# PIC32CM5164LS60064 register map
Vendor: Microchip Technology; Series: PIC32CMLS60; File version: 0
CPU: CM23 r0p0, selectable endian, MPU, no FPU, 2 interrupt priority bits
Registers are 32-bit, read-write, reset 0x0 unless marked. A register's access mark holds for its fields unless they carry their own. Offsets are from the block's base; [hi:lo] are bit positions; {n}, {i} and the like mark numbered series.

## PAC — Peripheral Access Controller
Base 0x40000000; register names take the prefix PAC_
Same registers: PAC_SEC 0x40000200 (register names take the prefix PAC_SEC_)
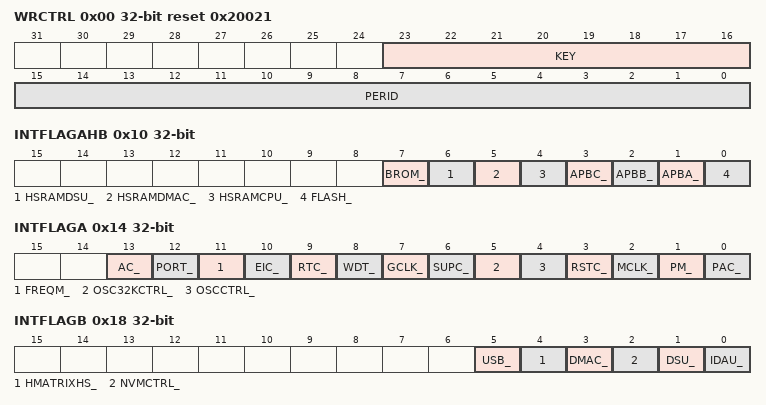
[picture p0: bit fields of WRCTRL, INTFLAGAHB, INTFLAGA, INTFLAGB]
0x00 WRCTRL reset 0x20021 — Write control
  [23:16] KEY — Peripheral access control key
    0=OFF (No action); 1=CLR (Clear protection); 2=SET (Set protection); 3=SETLCK (Set and lock protection); 4=SETSEC (Set IP secure); 5=SETNONSEC (Set IP non-secure); 6=SECLOCK (Lock IP security value)
  [15:0] PERID — Peripheral identifier
0x04 EVCTRL 8-bit — Event control
  [0] ERREO — Peripheral acess error event output
0x08 INTENCLR 8-bit — Interrupt enable clear
  [0] ERR — Peripheral access error interrupt disable
0x09 INTENSET 8-bit — Interrupt enable set
  [0] ERR — Peripheral access error interrupt enable
0x10 INTFLAGAHB — Bridge interrupt flag status
  [7] BROM_, [6] HSRAMDSU_, [5] HSRAMDMAC_, [4] HSRAMCPU_, [3] APBC_, [2] APBB_, [1] APBA_, [0] FLASH_
0x14 INTFLAGA — Peripheral interrupt flag status - Bridge A
  [13] AC_, [12] PORT_, [11] FREQM_, [10] EIC_, [9] RTC_, [8] WDT_, [7] GCLK_, [6] SUPC_, [5] OSC32KCTRL_, [4] OSCCTRL_, [3] RSTC_, [2] MCLK_, [1] PM_, [0] PAC_
0x18 INTFLAGB — Peripheral interrupt flag status - Bridge B
  [5] USB_, [4] HMATRIXHS_, [3] DMAC_, [2] NVMCTRL_, [1] DSU_, [0] IDAU_
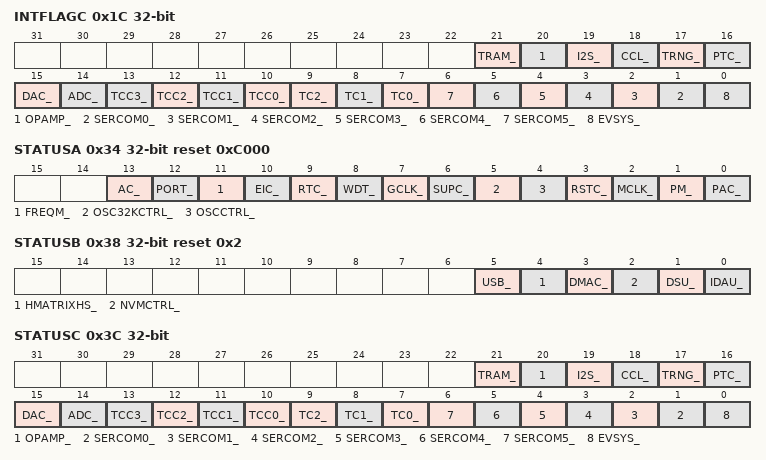
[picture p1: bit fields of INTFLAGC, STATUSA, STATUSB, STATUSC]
0x1C INTFLAGC — Peripheral interrupt flag status - Bridge C
  [21] TRAM_, [20] OPAMP_, [19] I2S_, [18] CCL_, [17] TRNG_, [16] PTC_, [15] DAC_, [14] ADC_, [n+10] TCC{n}_ (n=0..3), [9] TC2_, [8] TC1_, [7] TC0_, [n+1] SERCOM{n}_ (n=0..5), [0] EVSYS_
0x34 STATUSA ro reset 0xC000 — Peripheral write protection status - Bridge A
  [13] AC_ — AC APB Protect Enable
  [12] PORT_ — PORT APB Protect Enable
  [11] FREQM_ — FREQM APB Protect Enable
  [10] EIC_ — EIC APB Protect Enable
  [9] RTC_ — RTC APB Protect Enable
  [8] WDT_ — WDT APB Protect Enable
  [7] GCLK_ — GCLK APB Protect Enable
  [6] SUPC_ — SUPC APB Protect Enable
  [5] OSC32KCTRL_ — OSC32KCTRL APB Protect Enable
  [4] OSCCTRL_ — OSCCTRL APB Protect Enable
  [3] RSTC_ — RSTC APB Protect Enable
  [2] MCLK_ — MCLK APB Protect Enable
  [1] PM_ — PM APB Protect Enable
  [0] PAC_ — PAC APB Protect Enable
0x38 STATUSB ro reset 0x2 — Peripheral write protection status - Bridge B
  [5] USB_ — USB APB Protect Enable
  [4] HMATRIXHS_ — HMATRIXHS APB Protect Enable
  [3] DMAC_ — DMAC APB Protect Enable
  [2] NVMCTRL_ — NVMCTRL APB Protect Enable
  [1] DSU_ — DSU APB Protect Enable
  [0] IDAU_ — IDAU APB Protect Enable
0x3C STATUSC ro — Peripheral write protection status - Bridge C
  [21] TRAM_ — TRAM APB Protect Enable
  [20] OPAMP_ — OPAMP APB Protect Enable
  [19] I2S_ — I2S APB Protect Enable
  [18] CCL_ — CCL APB Protect Enable
  [17] TRNG_ — TRNG APB Protect Enable
  [16] PTC_ — PTC APB Protect Enable
  [15] DAC_ — DAC APB Protect Enable
  [14] ADC_ — ADC APB Protect Enable
  [n+10] TCC{n}_ (n=0..3) — TCC{n} APB Protect Enable
  [9] TC2_ — TC2 APB Protect Enable
  [8] TC1_ — TC1 APB Protect Enable
  [7] TC0_ — TC0 APB Protect Enable
  [n+1] SERCOM{n}_ (n=0..5) — SERCOM{n} APB Protect Enable
  [0] EVSYS_ — EVSYS APB Protect Enable
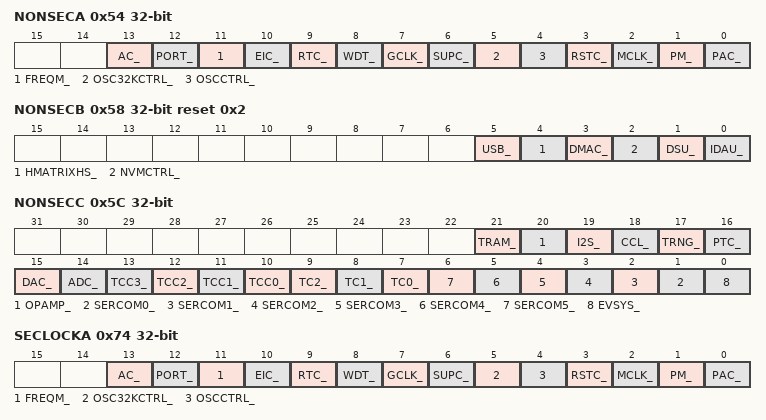
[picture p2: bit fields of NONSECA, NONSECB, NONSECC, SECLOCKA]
0x54 NONSECA ro — Peripheral non-secure status - Bridge A
  [13] AC_ — AC Non-Secure
  [12] PORT_ — PORT Non-Secure
  [11] FREQM_ — FREQM Non-Secure
  [10] EIC_ — EIC Non-Secure
  [9] RTC_ — RTC Non-Secure
  [8] WDT_ — WDT Non-Secure
  [7] GCLK_ — GCLK Non-Secure
  [6] SUPC_ — SUPC Non-Secure
  [5] OSC32KCTRL_ — OSC32KCTRL Non-Secure
  [4] OSCCTRL_ — OSCCTRL Non-Secure
  [3] RSTC_ — RSTC Non-Secure
  [2] MCLK_ — MCLK Non-Secure
  [1] PM_ — PM Non-Secure
  [0] PAC_ — PAC Non-Secure
0x58 NONSECB ro reset 0x2 — Peripheral non-secure status - Bridge B
  [5] USB_ — USB Non-Secure
  [4] HMATRIXHS_ — HMATRIXHS Non-Secure
  [3] DMAC_ — DMAC Non-Secure
  [2] NVMCTRL_ — NVMCTRL Non-Secure
  [1] DSU_ — DSU Non-Secure
  [0] IDAU_ — IDAU Non-Secure
0x5C NONSECC ro — Peripheral non-secure status - Bridge C
  [21] TRAM_ — TRAM Non-Secure
  [20] OPAMP_ — OPAMP Non-Secure
  [19] I2S_ — I2S Non-Secure
  [18] CCL_ — CCL Non-Secure
  [17] TRNG_ — TRNG Non-Secure
  [16] PTC_ — PTC Non-Secure
  [15] DAC_ — DAC Non-Secure
  [14] ADC_ — ADC Non-Secure
  [n+10] TCC{n}_ (n=0..3) — TCC{n} Non-Secure
  [9] TC2_ — TC2 Non-Secure
  [8] TC1_ — TC1 Non-Secure
  [7] TC0_ — TC0 Non-Secure
  [n+1] SERCOM{n}_ (n=0..5) — SERCOM{n} Non-Secure
  [0] EVSYS_ — EVSYS Non-Secure
0x74 SECLOCKA ro — Peripheral secure status locked - Bridge A
  [13] AC_ — AC Secure Status Locked
  [12] PORT_ — PORT Secure Status Locked
  [11] FREQM_ — FREQM Secure Status Locked
  [10] EIC_ — EIC Secure Status Locked
  [9] RTC_ — RTC Secure Status Locked
  [8] WDT_ — WDT Secure Status Locked
  [7] GCLK_ — GCLK Secure Status Locked
  [6] SUPC_ — SUPC Secure Status Locked
  [5] OSC32KCTRL_ — OSC32KCTRL Secure Status Locked
  [4] OSCCTRL_ — OSCCTRL Secure Status Locked
  [3] RSTC_ — RSTC Secure Status Locked
  [2] MCLK_ — MCLK Secure Status Locked
  [1] PM_ — PM Secure Status Locked
  [0] PAC_ — PAC Secure Status Locked
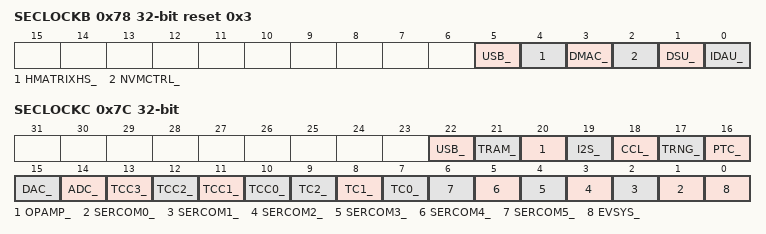
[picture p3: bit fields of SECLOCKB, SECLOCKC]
0x78 SECLOCKB ro reset 0x3 — Peripheral secure status locked - Bridge B
  [5] USB_ — USB Secure Status Locked
  [4] HMATRIXHS_ — HMATRIXHS Secure Status Locked
  [3] DMAC_ — DMAC Secure Status Locked
  [2] NVMCTRL_ — NVMCTRL Secure Status Locked
  [1] DSU_ — DSU Secure Status Locked
  [0] IDAU_ — IDAU Secure Status Locked
0x7C SECLOCKC ro — Peripheral secure status locked - Bridge C
  [22] USB_ — USB Secure Status Locked
  [21] TRAM_ — TRAM Secure Status Locked
  [20] OPAMP_ — OPAMP Secure Status Locked
  [19] I2S_ — I2S Secure Status Locked
  [18] CCL_ — CCL Secure Status Locked
  [17] TRNG_ — TRNG Secure Status Locked
  [16] PTC_ — PTC Secure Status Locked
  [15] DAC_ — DAC Secure Status Locked
  [14] ADC_ — ADC Secure Status Locked
  [n+10] TCC{n}_ (n=0..3) — TCC{n} Secure Status Locked
  [9] TC2_ — TC2 Secure Status Locked
  [8] TC1_ — TC1 Secure Status Locked
  [7] TC0_ — TC0 Secure Status Locked
  [n+1] SERCOM{n}_ (n=0..5) — SERCOM{n} Secure Status Locked
  [0] EVSYS_ — EVSYS Secure Status Locked

## Notices in the file
Copyright (c) 2017 Microchip Technology Inc.
SPDX-License-Identifier: Apache-2.0
Licensed under the Apache License, Version 2.0 (the "License");
you may not use this file except in compliance with the License.
You may obtain a copy of the License at
http://www.apache.org/licenses/LICENSE-2.0
Unless required by applicable law or agreed to in writing, software
distributed under the License is distributed on an "AS IS" BASIS,
WITHOUT WARRANTIES OR CONDITIONS OF ANY KIND, either express or implied.
See the License for the specific language governing permissions and
limitations under the License.
